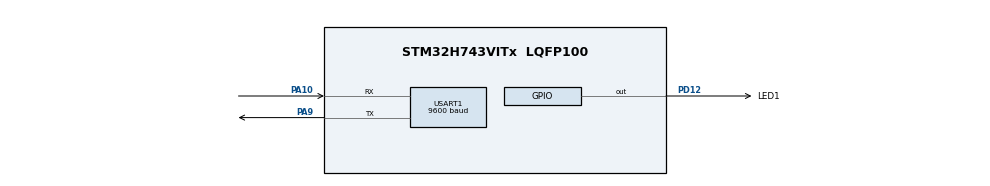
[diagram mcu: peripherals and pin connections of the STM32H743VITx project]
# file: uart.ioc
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CORTEX_M7.default_mode_Activation=1
FREERTOS.Tasks01=defaultTask,24,256,StartDefaultTask,Default,NULL,Static,defaultTaskBuffer,defaultTaskControlBlock
FREERTOS.configENABLE_FPU=1
FREERTOS.configUSE_NEWLIB_REENTRANT=1
Mcu.Family=STM32H7
Mcu.Name=STM32H743VITx
Mcu.Package=LQFP100
NVIC.PriorityGroup=NVIC_PRIORITYGROUP_4
NVIC.TIM1_UP_IRQn=true\:15\:0\:false\:false\:true\:false\:false\:true\:true
NVIC.TimeBase=TIM1_UP_IRQn
NVIC.TimeBaseIP=TIM1
PA10.GPIO_PuPd=GPIO_NOPULL
PA10.Mode=Asynchronous
PA10.Signal=USART1_RX
PA9.GPIO_PuPd=GPIO_NOPULL
PA9.Mode=Asynchronous
PA9.Signal=USART1_TX
PD12.GPIO_Label=LED1
PD12.GPIO_PuPd=GPIO_PULLUP
PD12.PinState=GPIO_PIN_RESET
PD12.Signal=GPIO_Output
ProjectManager.HeapSize=0x200
ProjectManager.StackSize=0x400
ProjectManager.TargetToolchain=STM32CubeIDE
RCC.ADCFreq_Value=129000000
RCC.APB1Freq_Value=64000000
RCC.APB2Freq_Value=32000000
RCC.APB3Freq_Value=64000000
RCC.APB4Freq_Value=64000000
RCC.CortexFreq_Value=64000000
RCC.D2PPRE2=RCC_APB2_DIV2
RCC.HCLKFreq_Value=64000000
RCC.SYSCLKFreq_VALUE=64000000
RCC.USBFreq_Value=129000000
USART1.BaudRate=9600
USART1.VirtualMode-Asynchronous=VM_ASYNC
VP_FREERTOS_VS_CMSIS_V2.Mode=CMSIS_V2
VP_MEMORYMAP_VS_MEMORYMAP.Mode=CurAppReg
VP_SYS_VS_tim1.Mode=TIM1
board=custom

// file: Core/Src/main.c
/* USER CODE BEGIN Header */
/**
  ******************************************************************************
  * @file           : main.c
  * @brief          : Main program body
  ******************************************************************************
  * @attention
  *
  * Copyright (c) 2026 STMicroelectronics.
  * All rights reserved.
  *
  * This software is licensed under terms that can be found in the LICENSE file
  * in the root directory of this software component.
  * If no LICENSE file comes with this software, it is provided AS-IS.
  *
  ******************************************************************************
  */
/* USER CODE END Header */
#include "main.h"
#include "cmsis_os.h"

/* USER CODE BEGIN Includes */
#include <stdio.h>
/* USER CODE END Includes */

typedef StaticTask_t osStaticThreadDef_t;

UART_HandleTypeDef huart1;

/* Definitions for defaultTask */
osThreadId_t defaultTaskHandle;
uint32_t defaultTaskBuffer[ 256 ];
osStaticThreadDef_t defaultTaskControlBlock;
const osThreadAttr_t defaultTask_attributes = {
  .name = "defaultTask",
  .cb_mem = &defaultTaskControlBlock,
  .cb_size = sizeof(defaultTaskControlBlock),
  .stack_mem = &defaultTaskBuffer[0],
  .stack_size = sizeof(defaultTaskBuffer),
  .priority = (osPriority_t) osPriorityNormal,
};

void SystemClock_Config(void);
static void MPU_Config(void);
static void MX_GPIO_Init(void);
static void MX_USART1_UART_Init(void);
void StartDefaultTask(void *argument);

int main(void)
{

  /* MPU Configuration--------------------------------------------------------*/
  MPU_Config();

  /* MCU Configuration--------------------------------------------------------*/

  /* Reset of all peripherals, Initializes the Flash interface and the Systick. */
  HAL_Init();

  /* Configure the system clock */
  SystemClock_Config();

  /* Initialize all configured peripherals */
  MX_GPIO_Init();
  MX_USART1_UART_Init();

  /* Init scheduler */
  osKernelInitialize();

  /* Create the thread(s) */
  /* creation of defaultTask */
  defaultTaskHandle = osThreadNew(StartDefaultTask, NULL, &defaultTask_attributes);

  /* Start scheduler */
  osKernelStart();

  /* We should never get here as control is now taken by the scheduler */

  /* Infinite loop */
  while (1)
  {

  }
}

void SystemClock_Config(void)
{
  RCC_OscInitTypeDef RCC_OscInitStruct = {0};
  RCC_ClkInitTypeDef RCC_ClkInitStruct = {0};

  /** Supply configuration update enable
  */
  HAL_PWREx_ConfigSupply(PWR_LDO_SUPPLY);

  /** Configure the main internal regulator output voltage
  */
  __HAL_PWR_VOLTAGESCALING_CONFIG(PWR_REGULATOR_VOLTAGE_SCALE3);

  while(!__HAL_PWR_GET_FLAG(PWR_FLAG_VOSRDY)) {}

  /** Initializes the RCC Oscillators according to the specified parameters
  * in the RCC_OscInitTypeDef structure.
  */
  RCC_OscInitStruct.OscillatorType = RCC_OSCILLATORTYPE_HSI;
  RCC_OscInitStruct.HSIState = RCC_HSI_DIV1;
  RCC_OscInitStruct.HSICalibrationValue = RCC_HSICALIBRATION_DEFAULT;
  RCC_OscInitStruct.PLL.PLLState = RCC_PLL_NONE;
  if (HAL_RCC_OscConfig(&RCC_OscInitStruct) != HAL_OK)
  {
    Error_Handler();
  }

  /** Initializes the CPU, AHB and APB buses clocks
  */
  RCC_ClkInitStruct.ClockType = RCC_CLOCKTYPE_HCLK|RCC_CLOCKTYPE_SYSCLK
                              |RCC_CLOCKTYPE_PCLK1|RCC_CLOCKTYPE_PCLK2
                              |RCC_CLOCKTYPE_D3PCLK1|RCC_CLOCKTYPE_D1PCLK1;
  RCC_ClkInitStruct.SYSCLKSource = RCC_SYSCLKSOURCE_HSI;
  RCC_ClkInitStruct.SYSCLKDivider = RCC_SYSCLK_DIV1;
  RCC_ClkInitStruct.AHBCLKDivider = RCC_HCLK_DIV1;
  RCC_ClkInitStruct.APB3CLKDivider = RCC_APB3_DIV1;
  RCC_ClkInitStruct.APB1CLKDivider = RCC_APB1_DIV1;
  RCC_ClkInitStruct.APB2CLKDivider = RCC_APB2_DIV2;
  RCC_ClkInitStruct.APB4CLKDivider = RCC_APB4_DIV1;

  if (HAL_RCC_ClockConfig(&RCC_ClkInitStruct, FLASH_LATENCY_1) != HAL_OK)
  {
    Error_Handler();
  }
}

static void MX_USART1_UART_Init(void)
{

  huart1.Instance = USART1;
  huart1.Init.BaudRate = 9600;
  huart1.Init.WordLength = UART_WORDLENGTH_8B;
  huart1.Init.StopBits = UART_STOPBITS_1;
  huart1.Init.Parity = UART_PARITY_NONE;
  huart1.Init.Mode = UART_MODE_TX_RX;
  huart1.Init.HwFlowCtl = UART_HWCONTROL_NONE;
  huart1.Init.OverSampling = UART_OVERSAMPLING_16;
  huart1.Init.OneBitSampling = UART_ONE_BIT_SAMPLE_DISABLE;
  huart1.Init.ClockPrescaler = UART_PRESCALER_DIV1;
  huart1.AdvancedInit.AdvFeatureInit = UART_ADVFEATURE_NO_INIT;
  if (HAL_UART_Init(&huart1) != HAL_OK)
  {
    Error_Handler();
  }
  if (HAL_UARTEx_SetTxFifoThreshold(&huart1, UART_TXFIFO_THRESHOLD_1_8) != HAL_OK)
  {
    Error_Handler();
  }
  if (HAL_UARTEx_SetRxFifoThreshold(&huart1, UART_RXFIFO_THRESHOLD_1_8) != HAL_OK)
  {
    Error_Handler();
  }
  if (HAL_UARTEx_DisableFifoMode(&huart1) != HAL_OK)
  {
    Error_Handler();
  }

}

static void MX_GPIO_Init(void)
{
  GPIO_InitTypeDef GPIO_InitStruct = {0};

  /* GPIO Ports Clock Enable */
  __HAL_RCC_GPIOD_CLK_ENABLE();
  __HAL_RCC_GPIOA_CLK_ENABLE();

  /*Configure GPIO pin Output Level */
  HAL_GPIO_WritePin(LED1_GPIO_Port, LED1_Pin, GPIO_PIN_RESET);

  /*Configure GPIO pin : LED1_Pin */
  GPIO_InitStruct.Pin = LED1_Pin;
  GPIO_InitStruct.Mode = GPIO_MODE_OUTPUT_PP;
  GPIO_InitStruct.Pull = GPIO_PULLUP;
  GPIO_InitStruct.Speed = GPIO_SPEED_FREQ_LOW;
  HAL_GPIO_Init(LED1_GPIO_Port, &GPIO_InitStruct);

}

void StartDefaultTask(void *argument)
{
  /* USER CODE BEGIN 5 */
  /* Infinite loop */
  uint8_t rx_buf[64];
  uint8_t rx_idx = 0;
  uint8_t rx_byte;
  uint32_t counter = 1;

  for(;;)
  {
    HAL_StatusTypeDef status = HAL_UART_Receive(&huart1, &rx_byte, 1, 50);

    if (status == HAL_OK) {
      if (rx_byte == '\r' || rx_byte == '\n') {
        if (rx_idx > 0) {
          rx_buf[rx_idx] = '\0';
          char tx_buf[80];
          int len = snprintf(tx_buf, sizeof(tx_buf), "%s:%lu\r\n", (char*)rx_buf, (unsigned long)counter);
          HAL_UART_Transmit(&huart1, (uint8_t*)tx_buf, len, HAL_MAX_DELAY);
          HAL_GPIO_TogglePin(LED1_GPIO_Port, LED1_Pin);
          counter++;
          rx_idx = 0;
        }
      } else {
        if (rx_idx < sizeof(rx_buf) - 1) {
          rx_buf[rx_idx++] = rx_byte;
        } else {
          rx_idx = 0;
        }
      }
    }
  }
  /* USER CODE END 5 */
}

 /* MPU Configuration */

void MPU_Config(void)
{
  MPU_Region_InitTypeDef MPU_InitStruct = {0};

  /* Disables the MPU */
  HAL_MPU_Disable();

  /** Initializes and configures the Region and the memory to be protected
  */
  MPU_InitStruct.Enable = MPU_REGION_ENABLE;
  MPU_InitStruct.Number = MPU_REGION_NUMBER0;
  MPU_InitStruct.BaseAddress = 0x0;
  MPU_InitStruct.Size = MPU_REGION_SIZE_4GB;
  MPU_InitStruct.SubRegionDisable = 0x87;
  MPU_InitStruct.TypeExtField = MPU_TEX_LEVEL0;
  MPU_InitStruct.AccessPermission = MPU_REGION_NO_ACCESS;
  MPU_InitStruct.DisableExec = MPU_INSTRUCTION_ACCESS_DISABLE;
  MPU_InitStruct.IsShareable = MPU_ACCESS_SHAREABLE;
  MPU_InitStruct.IsCacheable = MPU_ACCESS_NOT_CACHEABLE;
  MPU_InitStruct.IsBufferable = MPU_ACCESS_NOT_BUFFERABLE;

  HAL_MPU_ConfigRegion(&MPU_InitStruct);
  /* Enables the MPU */
  HAL_MPU_Enable(MPU_PRIVILEGED_DEFAULT);

}

void HAL_TIM_PeriodElapsedCallback(TIM_HandleTypeDef *htim)
{
  if (htim->Instance == TIM1)
  {
    HAL_IncTick();
  }
}

void Error_Handler(void)
{
  __disable_irq();
  while (1)
  {
  }
}
